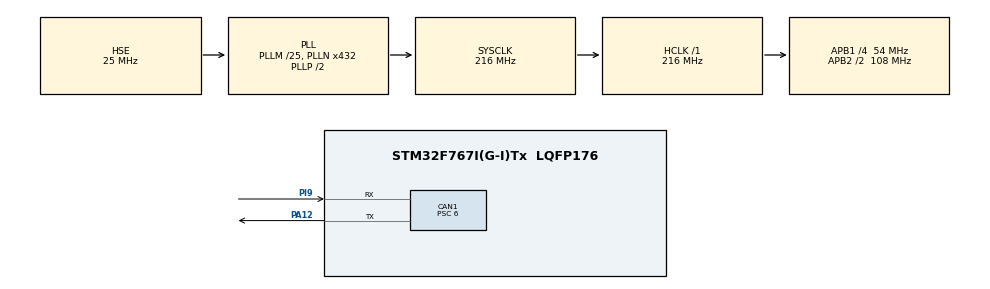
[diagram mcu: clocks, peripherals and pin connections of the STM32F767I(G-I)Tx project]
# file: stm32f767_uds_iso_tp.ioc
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CAN1.BS1=CAN_BS1_11TQ
CAN1.BS2=CAN_BS2_6TQ
CAN1.CalculateBaudRate=500000
CAN1.CalculateTimeBit=2000
CAN1.CalculateTimeQuantum=111.11111111111111
CAN1.Prescaler=6
CORTEX_M7.default_mode_Activation=1
Mcu.Family=STM32F7
Mcu.Name=STM32F767I(G-I)Tx
Mcu.Package=LQFP176
NVIC.CAN1_RX0_IRQn=true\:0\:0\:false\:false\:true\:true\:true\:true
NVIC.CAN1_RX1_IRQn=true\:0\:0\:false\:false\:true\:true\:true\:true
NVIC.CAN1_SCE_IRQn=true\:0\:0\:false\:false\:true\:true\:true\:true
NVIC.CAN1_TX_IRQn=true\:0\:0\:false\:false\:true\:true\:true\:true
NVIC.PriorityGroup=NVIC_PRIORITYGROUP_4
NVIC.TIM7_IRQn=true\:0\:0\:false\:false\:true\:true\:true\:true
PA12.Mode=CAN_Activate
PA12.Signal=CAN1_TX
PH0/OSC_IN.Mode=HSE-External-Oscillator
PH0/OSC_IN.Signal=RCC_OSC_IN
PH1/OSC_OUT.Mode=HSE-External-Oscillator
PH1/OSC_OUT.Signal=RCC_OSC_OUT
PI9.Mode=CAN_Activate
PI9.Signal=CAN1_RX
ProjectManager.HeapSize=0x200
ProjectManager.StackSize=0x400
ProjectManager.TargetToolchain=CMake
RCC.AHBFreq_Value=216000000
RCC.APB1CLKDivider=RCC_HCLK_DIV4
RCC.APB1Freq_Value=54000000
RCC.APB1TimFreq_Value=108000000
RCC.APB2CLKDivider=RCC_HCLK_DIV2
RCC.APB2Freq_Value=108000000
RCC.APB2TimFreq_Value=216000000
RCC.CortexFreq_Value=216000000
RCC.HCLKFreq_Value=216000000
RCC.HSE_VALUE=25000000
RCC.HSI_VALUE=16000000
RCC.LSE_VALUE=32768
RCC.PLLM=25
RCC.PLLN=432
RCC.PLLSourceVirtual=RCC_PLLSOURCE_HSE
RCC.SYSCLKFreq_VALUE=216000000
RCC.SYSCLKSource=RCC_SYSCLKSOURCE_PLLCLK
RCC.USBFreq_Value=216000000
RCC.VCOOutputFreq_Value=432000000
TIM7.Period=1000-1
TIM7.Prescaler=108-1
VP_TIM7_VS_ClockSourceINT.Mode=Enable_Timer
board=custom

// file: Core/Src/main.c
/* USER CODE BEGIN Header */
/**
  ******************************************************************************
  * @file           : main.c
  * @brief          : Main program body
  ******************************************************************************
  * @attention
  *
  * Copyright (c) 2026 STMicroelectronics.
  * All rights reserved.
  *
  * This software is licensed under terms that can be found in the LICENSE file
  * in the root directory of this software component.
  * If no LICENSE file comes with this software, it is provided AS-IS.
  *
  ******************************************************************************
  */
/* USER CODE END Header */
#include "main.h"

/* USER CODE BEGIN Includes */
#include "can_transport.h"
#include "uds_app.h"
#include "uds_platform.h"
/* USER CODE END Includes */

CAN_HandleTypeDef hcan1;

TIM_HandleTypeDef htim7;

/* USER CODE BEGIN PV */
static UdsCanTransport uds_transport;
/* USER CODE END PV */

void SystemClock_Config(void);
static void MPU_Config(void);
static void MX_GPIO_Init(void);
static void MX_CAN1_Init(void);
static void MX_TIM7_Init(void);

/* USER CODE BEGIN 0 */
void HAL_CAN_RxFifo0MsgPendingCallback(CAN_HandleTypeDef *hcan) {
    if (hcan != &hcan1)
        return;
    CAN_RxHeaderTypeDef header = {0};
    uint8_t data[8] = {0};
    if (HAL_CAN_GetRxMessage(hcan, CAN_RX_FIFO0, &header, data) == HAL_OK) {
        uds_app_rx_from_isr(header.StdId, data, (uint8_t)header.DLC);
    }
}
/* USER CODE END 0 */

int main(void)
{

  /* MPU Configuration--------------------------------------------------------*/
  MPU_Config();

  /* MCU Configuration--------------------------------------------------------*/

  /* Reset of all peripherals, Initializes the Flash interface and the Systick. */
  HAL_Init();

  /* USER CODE BEGIN Init */
  /* HAL_Init() provides the millisecond time base used by the endpoint. */
  /* USER CODE END Init */

  /* Configure the system clock */
  SystemClock_Config();

  /* Initialize all configured peripherals */
  MX_GPIO_Init();
  MX_CAN1_Init();
  MX_TIM7_Init();
  /* USER CODE BEGIN 2 */
  CAN_FilterTypeDef sFilterConfig = {0};
  sFilterConfig.FilterBank = 0;
  sFilterConfig.FilterMode = CAN_FILTERMODE_IDMASK;
  sFilterConfig.FilterScale = CAN_FILTERSCALE_32BIT;
  sFilterConfig.FilterIdHigh = 0x0000;
  sFilterConfig.FilterIdLow = 0x0000;
  sFilterConfig.FilterMaskIdHigh = 0x0000;
  sFilterConfig.FilterMaskIdLow = 0x0000;
  sFilterConfig.FilterFIFOAssignment = CAN_RX_FIFO0;
  sFilterConfig.FilterActivation = ENABLE;
  sFilterConfig.SlaveStartFilterBank = 14;
  if (HAL_CAN_ConfigFilter(&hcan1, &sFilterConfig) != HAL_OK) {
    uds_platform_error();
  }

  uds_can_transport_init(&uds_transport, &hcan1, 0x7E0U, 0x7E8U);
  uds_app_init(&uds_transport, uds_platform_now_ms());
  if (HAL_CAN_Start(&hcan1) != HAL_OK ||
      HAL_CAN_ActivateNotification(&hcan1, CAN_IT_RX_FIFO0_MSG_PENDING) != HAL_OK) {
      uds_platform_error();
  }
  /* USER CODE END 2 */

  /* Infinite loop */
  /* USER CODE BEGIN WHILE */
  while (1)
  {
    uds_app_process(uds_platform_now_ms());
    /* USER CODE END WHILE */

  }
}

void SystemClock_Config(void)
{
  RCC_OscInitTypeDef RCC_OscInitStruct = {0};
  RCC_ClkInitTypeDef RCC_ClkInitStruct = {0};

  /** Configure the main internal regulator output voltage
  */
  __HAL_RCC_PWR_CLK_ENABLE();
  __HAL_PWR_VOLTAGESCALING_CONFIG(PWR_REGULATOR_VOLTAGE_SCALE1);

  /** Initializes the RCC Oscillators according to the specified parameters
  * in the RCC_OscInitTypeDef structure.
  */
  RCC_OscInitStruct.OscillatorType = RCC_OSCILLATORTYPE_HSE;
  RCC_OscInitStruct.HSEState = RCC_HSE_ON;
  RCC_OscInitStruct.PLL.PLLState = RCC_PLL_ON;
  RCC_OscInitStruct.PLL.PLLSource = RCC_PLLSOURCE_HSE;
  RCC_OscInitStruct.PLL.PLLM = 25;
  RCC_OscInitStruct.PLL.PLLN = 432;
  RCC_OscInitStruct.PLL.PLLP = RCC_PLLP_DIV2;
  RCC_OscInitStruct.PLL.PLLQ = 2;
  RCC_OscInitStruct.PLL.PLLR = 2;
  if (HAL_RCC_OscConfig(&RCC_OscInitStruct) != HAL_OK)
  {
    Error_Handler();
  }

  /** Activate the Over-Drive mode
  */
  if (HAL_PWREx_EnableOverDrive() != HAL_OK)
  {
    Error_Handler();
  }

  /** Initializes the CPU, AHB and APB buses clocks
  */
  RCC_ClkInitStruct.ClockType = RCC_CLOCKTYPE_HCLK|RCC_CLOCKTYPE_SYSCLK
                              |RCC_CLOCKTYPE_PCLK1|RCC_CLOCKTYPE_PCLK2;
  RCC_ClkInitStruct.SYSCLKSource = RCC_SYSCLKSOURCE_PLLCLK;
  RCC_ClkInitStruct.AHBCLKDivider = RCC_SYSCLK_DIV1;
  RCC_ClkInitStruct.APB1CLKDivider = RCC_HCLK_DIV4;
  RCC_ClkInitStruct.APB2CLKDivider = RCC_HCLK_DIV2;

  if (HAL_RCC_ClockConfig(&RCC_ClkInitStruct, FLASH_LATENCY_7) != HAL_OK)
  {
    Error_Handler();
  }
}

static void MX_CAN1_Init(void)
{

  hcan1.Instance = CAN1;
  hcan1.Init.Prescaler = 6;
  hcan1.Init.Mode = CAN_MODE_NORMAL;
  hcan1.Init.SyncJumpWidth = CAN_SJW_1TQ;
  hcan1.Init.TimeSeg1 = CAN_BS1_11TQ;
  hcan1.Init.TimeSeg2 = CAN_BS2_6TQ;
  hcan1.Init.TimeTriggeredMode = DISABLE;
  hcan1.Init.AutoBusOff = DISABLE;
  hcan1.Init.AutoWakeUp = DISABLE;
  hcan1.Init.AutoRetransmission = DISABLE;
  hcan1.Init.ReceiveFifoLocked = DISABLE;
  hcan1.Init.TransmitFifoPriority = DISABLE;
  if (HAL_CAN_Init(&hcan1) != HAL_OK)
  {
    Error_Handler();
  }

}

static void MX_TIM7_Init(void)
{

  TIM_MasterConfigTypeDef sMasterConfig = {0};

  htim7.Instance = TIM7;
  htim7.Init.Prescaler = 108-1;
  htim7.Init.CounterMode = TIM_COUNTERMODE_UP;
  htim7.Init.Period = 1000-1;
  htim7.Init.AutoReloadPreload = TIM_AUTORELOAD_PRELOAD_DISABLE;
  if (HAL_TIM_Base_Init(&htim7) != HAL_OK)
  {
    Error_Handler();
  }
  sMasterConfig.MasterOutputTrigger = TIM_TRGO_RESET;
  sMasterConfig.MasterSlaveMode = TIM_MASTERSLAVEMODE_DISABLE;
  if (HAL_TIMEx_MasterConfigSynchronization(&htim7, &sMasterConfig) != HAL_OK)
  {
    Error_Handler();
  }

}

static void MX_GPIO_Init(void)
{

  /* GPIO Ports Clock Enable */
  __HAL_RCC_GPIOI_CLK_ENABLE();
  __HAL_RCC_GPIOH_CLK_ENABLE();
  __HAL_RCC_GPIOA_CLK_ENABLE();

}

 /* MPU Configuration */

void MPU_Config(void)
{
  MPU_Region_InitTypeDef MPU_InitStruct = {0};

  /* Disables the MPU */
  HAL_MPU_Disable();

  /** Initializes and configures the Region and the memory to be protected
  */
  MPU_InitStruct.Enable = MPU_REGION_ENABLE;
  MPU_InitStruct.Number = MPU_REGION_NUMBER0;
  MPU_InitStruct.BaseAddress = 0x0;
  MPU_InitStruct.Size = MPU_REGION_SIZE_4GB;
  MPU_InitStruct.SubRegionDisable = 0x87;
  MPU_InitStruct.TypeExtField = MPU_TEX_LEVEL0;
  MPU_InitStruct.AccessPermission = MPU_REGION_NO_ACCESS;
  MPU_InitStruct.DisableExec = MPU_INSTRUCTION_ACCESS_DISABLE;
  MPU_InitStruct.IsShareable = MPU_ACCESS_SHAREABLE;
  MPU_InitStruct.IsCacheable = MPU_ACCESS_NOT_CACHEABLE;
  MPU_InitStruct.IsBufferable = MPU_ACCESS_NOT_BUFFERABLE;

  HAL_MPU_ConfigRegion(&MPU_InitStruct);
  /* Enables the MPU */
  HAL_MPU_Enable(MPU_PRIVILEGED_DEFAULT);

}

void Error_Handler(void)
{
  __disable_irq();
  while (1)
  {
  }
}
